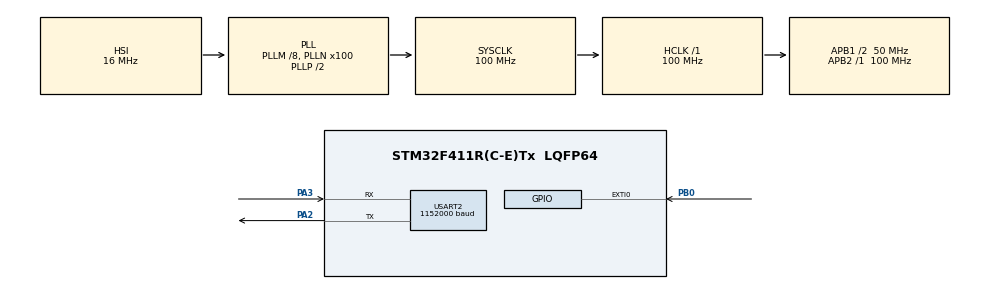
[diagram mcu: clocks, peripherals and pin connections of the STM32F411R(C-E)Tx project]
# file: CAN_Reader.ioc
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Dma.Request0=USART2_TX
Dma.USART2_TX.0.Direction=DMA_MEMORY_TO_PERIPH
Dma.USART2_TX.0.FIFOMode=DMA_FIFOMODE_DISABLE
Dma.USART2_TX.0.Instance=DMA1_Stream6
Dma.USART2_TX.0.MemDataAlignment=DMA_MDATAALIGN_BYTE
Dma.USART2_TX.0.MemInc=DMA_MINC_ENABLE
Dma.USART2_TX.0.Mode=DMA_NORMAL
Dma.USART2_TX.0.PeriphDataAlignment=DMA_PDATAALIGN_BYTE
Dma.USART2_TX.0.PeriphInc=DMA_PINC_DISABLE
Dma.USART2_TX.0.Priority=DMA_PRIORITY_LOW
Mcu.Family=STM32F4
Mcu.Name=STM32F411R(C-E)Tx
Mcu.Package=LQFP64
NVIC.DMA1_Stream6_IRQn=true\:0\:0\:false\:false\:true\:false\:true\:true
NVIC.EXTI0_IRQn=true\:0\:0\:false\:false\:true\:true\:true\:true
NVIC.PriorityGroup=NVIC_PRIORITYGROUP_4
NVIC.USART2_IRQn=true\:0\:0\:false\:false\:true\:true\:true\:true
PA2.Mode=Asynchronous
PA2.Signal=USART2_TX
PA3.Mode=Asynchronous
PA3.Signal=USART2_RX
PB0.GPIO_ModeDefaultEXTI=GPIO_MODE_IT_RISING_FALLING
PB0.GPIO_PuPd=GPIO_PULLUP
PB0.Signal=GPXTI0
ProjectManager.HeapSize=0x200
ProjectManager.StackSize=0x400
ProjectManager.TargetToolchain=STM32CubeIDE
RCC.48MHZClocksFreq_Value=50000000
RCC.AHBFreq_Value=100000000
RCC.APB1CLKDivider=RCC_HCLK_DIV2
RCC.APB1Freq_Value=50000000
RCC.APB1TimFreq_Value=100000000
RCC.APB2Freq_Value=100000000
RCC.APB2TimFreq_Value=100000000
RCC.CortexFreq_Value=100000000
RCC.HCLKFreq_Value=100000000
RCC.HSE_VALUE=25000000
RCC.HSI_VALUE=16000000
RCC.LSE_VALUE=32768
RCC.PLLM=8
RCC.PLLN=100
RCC.SYSCLKFreq_VALUE=100000000
RCC.SYSCLKSource=RCC_SYSCLKSOURCE_PLLCLK
RCC.VCOOutputFreq_Value=200000000
TIM2.Prescaler=9
USART2.BaudRate=1152000
USART2.VirtualMode=VM_ASYNC
VP_TIM2_VS_ClockSourceITR.Mode=TriggerSource_ITR0
board=custom

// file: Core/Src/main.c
/* USER CODE BEGIN Header */
/**
  ******************************************************************************
  * @file           : main.c
  * @brief          : Main program body
  ******************************************************************************
  * @attention
  *
  * Copyright (c) 2025 STMicroelectronics.
  * All rights reserved.
  *
  * This software is licensed under terms that can be found in the LICENSE file
  * in the root directory of this software component.
  * If no LICENSE file comes with this software, it is provided AS-IS.
  *
  ******************************************************************************
  */
/* USER CODE END Header */
#include "main.h"

/* USER CODE BEGIN PTD */
typedef struct {
	uint8_t start;
    uint8_t level;
    uint8_t pin;
    uint32_t timestamp;
} EdgeRecord;
/* USER CODE END PTD */

/* USER CODE BEGIN PM */
#define BUFFER_SIZE 2048
#define FRAME_IDLE_THRESHOLD 15000
/* USER CODE END PM */

TIM_HandleTypeDef htim2;

UART_HandleTypeDef huart2;
DMA_HandleTypeDef hdma_usart2_tx;

/* USER CODE BEGIN PV */
EdgeRecord record_buffer[BUFFER_SIZE];

volatile uint16_t record_index = 0;
volatile uint8_t dma_busy = 0;

uint8_t timer_started = 0;
uint8_t level = 0;

uint32_t now = 0;
uint32_t current_time = 0;
uint32_t last_timestamp = 0;
/* USER CODE END PV */

void SystemClock_Config(void);
static void MX_GPIO_Init(void);
static void MX_DMA_Init(void);
static void MX_USART2_UART_Init(void);
static void MX_TIM2_Init(void);
/* USER CODE BEGIN PFP */
void Read_Pin_Data(uint16_t GPIO_Pin);
/* USER CODE END PFP */

/* USER CODE BEGIN 0 */

void HAL_GPIO_EXTI_Callback(uint16_t GPIO_Pin)
{

    if (GPIO_Pin == GPIO_PIN_0 && !dma_busy)
    {
    	Read_Pin_Data(GPIO_Pin);
    }

}

void Read_Pin_Data(uint16_t GPIO_Pin)
{

	if (!timer_started)
	{
		__HAL_TIM_SET_COUNTER(&htim2, 0);
		HAL_TIM_Base_Start(&htim2);
		timer_started = 1;
	}

	now = __HAL_TIM_GET_COUNTER(&htim2);
	level = (GPIOB->IDR & GPIO_Pin) ? 1 : 0;

	record_buffer[record_index].start = 17;
	record_buffer[record_index].level = level;
	record_buffer[record_index].pin = GPIO_Pin;
	record_buffer[record_index].timestamp = now;
	record_index++;
}

/* USER CODE END 0 */

int main(void)
{

  /* MCU Configuration--------------------------------------------------------*/

  /* Reset of all peripherals, Initializes the Flash interface and the Systick. */
  HAL_Init();

  /* Configure the system clock */
  SystemClock_Config();

  /* Initialize all configured peripherals */
  MX_GPIO_Init();
  MX_DMA_Init();
  MX_USART2_UART_Init();
  MX_TIM2_Init();

  /* Infinite loop */
  /* USER CODE BEGIN WHILE */
  while (1)
  {
	  if (record_index > 0)
	  {
		  current_time = __HAL_TIM_GET_COUNTER(&htim2);
		  last_timestamp = record_buffer[record_index - 1].timestamp;

		  if (current_time >= FRAME_IDLE_THRESHOLD)
		  {
	  		  __HAL_TIM_SET_COUNTER(&htim2, 0);
			  HAL_TIM_Base_Stop(&htim2);
			  timer_started = 0;
			  dma_busy = 1;
			  HAL_NVIC_DisableIRQ(EXTI0_IRQn);
			  HAL_UART_Transmit_DMA(&huart2, (uint8_t*)record_buffer, sizeof(EdgeRecord) * record_index);
			  record_index = 0;
		  }
	  }

    /* USER CODE END WHILE */

  }
}

void SystemClock_Config(void)
{
  RCC_OscInitTypeDef RCC_OscInitStruct = {0};
  RCC_ClkInitTypeDef RCC_ClkInitStruct = {0};

  /** Configure the main internal regulator output voltage
  */
  __HAL_RCC_PWR_CLK_ENABLE();
  __HAL_PWR_VOLTAGESCALING_CONFIG(PWR_REGULATOR_VOLTAGE_SCALE1);

  /** Initializes the RCC Oscillators according to the specified parameters
  * in the RCC_OscInitTypeDef structure.
  */
  RCC_OscInitStruct.OscillatorType = RCC_OSCILLATORTYPE_HSI;
  RCC_OscInitStruct.HSIState = RCC_HSI_ON;
  RCC_OscInitStruct.HSICalibrationValue = RCC_HSICALIBRATION_DEFAULT;
  RCC_OscInitStruct.PLL.PLLState = RCC_PLL_ON;
  RCC_OscInitStruct.PLL.PLLSource = RCC_PLLSOURCE_HSI;
  RCC_OscInitStruct.PLL.PLLM = 8;
  RCC_OscInitStruct.PLL.PLLN = 100;
  RCC_OscInitStruct.PLL.PLLP = RCC_PLLP_DIV2;
  RCC_OscInitStruct.PLL.PLLQ = 4;
  if (HAL_RCC_OscConfig(&RCC_OscInitStruct) != HAL_OK)
  {
    Error_Handler();
  }

  /** Initializes the CPU, AHB and APB buses clocks
  */
  RCC_ClkInitStruct.ClockType = RCC_CLOCKTYPE_HCLK|RCC_CLOCKTYPE_SYSCLK
                              |RCC_CLOCKTYPE_PCLK1|RCC_CLOCKTYPE_PCLK2;
  RCC_ClkInitStruct.SYSCLKSource = RCC_SYSCLKSOURCE_PLLCLK;
  RCC_ClkInitStruct.AHBCLKDivider = RCC_SYSCLK_DIV1;
  RCC_ClkInitStruct.APB1CLKDivider = RCC_HCLK_DIV2;
  RCC_ClkInitStruct.APB2CLKDivider = RCC_HCLK_DIV1;

  if (HAL_RCC_ClockConfig(&RCC_ClkInitStruct, FLASH_LATENCY_3) != HAL_OK)
  {
    Error_Handler();
  }
}

static void MX_TIM2_Init(void)
{

  TIM_SlaveConfigTypeDef sSlaveConfig = {0};
  TIM_MasterConfigTypeDef sMasterConfig = {0};

  htim2.Instance = TIM2;
  htim2.Init.Prescaler = 9;
  htim2.Init.CounterMode = TIM_COUNTERMODE_UP;
  htim2.Init.Period = 4294967295;
  htim2.Init.ClockDivision = TIM_CLOCKDIVISION_DIV1;
  htim2.Init.AutoReloadPreload = TIM_AUTORELOAD_PRELOAD_DISABLE;
  if (HAL_TIM_Base_Init(&htim2) != HAL_OK)
  {
    Error_Handler();
  }
  sSlaveConfig.SlaveMode = TIM_SLAVEMODE_DISABLE;
  sSlaveConfig.InputTrigger = TIM_TS_ITR0;
  if (HAL_TIM_SlaveConfigSynchro(&htim2, &sSlaveConfig) != HAL_OK)
  {
    Error_Handler();
  }
  sMasterConfig.MasterOutputTrigger = TIM_TRGO_RESET;
  sMasterConfig.MasterSlaveMode = TIM_MASTERSLAVEMODE_DISABLE;
  if (HAL_TIMEx_MasterConfigSynchronization(&htim2, &sMasterConfig) != HAL_OK)
  {
    Error_Handler();
  }

}

static void MX_USART2_UART_Init(void)
{

  huart2.Instance = USART2;
  huart2.Init.BaudRate = 1152000;
  huart2.Init.WordLength = UART_WORDLENGTH_8B;
  huart2.Init.StopBits = UART_STOPBITS_1;
  huart2.Init.Parity = UART_PARITY_NONE;
  huart2.Init.Mode = UART_MODE_TX_RX;
  huart2.Init.HwFlowCtl = UART_HWCONTROL_NONE;
  huart2.Init.OverSampling = UART_OVERSAMPLING_16;
  if (HAL_UART_Init(&huart2) != HAL_OK)
  {
    Error_Handler();
  }

}

static void MX_DMA_Init(void)
{

  /* DMA controller clock enable */
  __HAL_RCC_DMA1_CLK_ENABLE();

  /* DMA interrupt init */
  /* DMA1_Stream6_IRQn interrupt configuration */
  HAL_NVIC_SetPriority(DMA1_Stream6_IRQn, 0, 0);
  HAL_NVIC_EnableIRQ(DMA1_Stream6_IRQn);

}

static void MX_GPIO_Init(void)
{
  GPIO_InitTypeDef GPIO_InitStruct = {0};

  /* GPIO Ports Clock Enable */
  __HAL_RCC_GPIOA_CLK_ENABLE();
  __HAL_RCC_GPIOB_CLK_ENABLE();

  /*Configure GPIO pin : PB0 */
  GPIO_InitStruct.Pin = GPIO_PIN_0;
  GPIO_InitStruct.Mode = GPIO_MODE_IT_RISING_FALLING;
  GPIO_InitStruct.Pull = GPIO_PULLUP;
  HAL_GPIO_Init(GPIOB, &GPIO_InitStruct);

  /* EXTI interrupt init*/
  HAL_NVIC_SetPriority(EXTI0_IRQn, 0, 0);
  HAL_NVIC_EnableIRQ(EXTI0_IRQn);

}

/* USER CODE BEGIN 4 */

void HAL_UART_TxCpltCallback(UART_HandleTypeDef *huart)
{
    if (huart->Instance == USART2)
    {
        dma_busy = 0;

        HAL_NVIC_EnableIRQ(EXTI0_IRQn);
    }
}

/* USER CODE END 4 */

void Error_Handler(void)
{
  __disable_irq();
  while (1)
  {
  }
}
